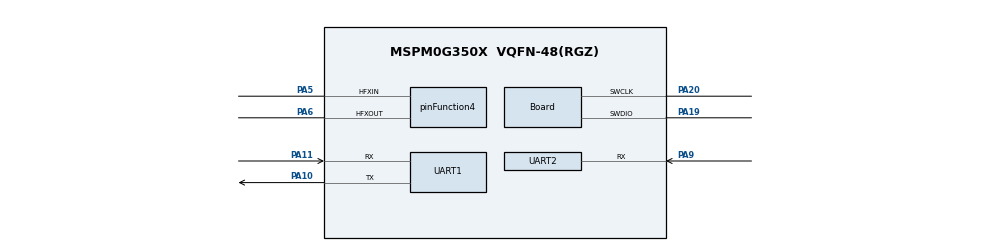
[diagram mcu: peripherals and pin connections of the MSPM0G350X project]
/**
 * @cliArgs --device "MSPM0G350X" --part "Default" --package "VQFN-48(RGZ)" --product "mspm0_sdk@2.05.01.01"
 * @versions {"tool":"1.24.0+4110"}
 */

/**
 * Import the modules used in this configuration.
 */
const SYSCTL  = scripting.addModule("/ti/driverlib/SYSCTL");
const SYSTICK = scripting.addModule("/ti/driverlib/SYSTICK");
const UART    = scripting.addModule("/ti/driverlib/UART", {}, false);
const UART1   = UART.addInstance();
const UART2   = UART.addInstance();

/**
 * Write custom configuration values to the imported modules.
 */
const divider6       = system.clockTree["PLL_CLK2X_DIV"];
divider6.divideValue = 4;

const divider9       = system.clockTree["UDIV"];
divider9.divideValue = 2;

const multiplier2         = system.clockTree["PLL_QDIV"];
multiplier2.multiplyValue = 4;

const mux4       = system.clockTree["EXHFMUX"];
mux4.inputSelect = "EXHFMUX_XTAL";

const mux8       = system.clockTree["HSCLKMUX"];
mux8.inputSelect = "HSCLKMUX_SYSPLL2X";

const mux12       = system.clockTree["SYSPLLMUX"];
mux12.inputSelect = "zSYSPLLMUX_HFCLK";

const pinFunction4                        = system.clockTree["HFXT"];
pinFunction4.inputFreq                    = 40;
pinFunction4.enable                       = true;
pinFunction4.HFXTStartup                  = 10;
pinFunction4.peripheral.$assign           = "SYSCTL";
pinFunction4.peripheral.hfxInPin.$assign  = "PA5";
pinFunction4.peripheral.hfxOutPin.$assign = "PA6";

SYSCTL.forceDefaultClkConfig = true;
SYSCTL.clockTreeEn           = true;
scripting.suppress("For best practices when the CPUCLK is running at 32MHz and above, clear the flash status bit using DL_FlashCTL_executeClearStatus\\(\\) before executing any flash operation\\. Otherwise there may be false positives\\.", SYSCTL);

const Board                       = scripting.addModule("/ti/driverlib/Board", {}, false);
Board.peripheral.$assign          = "DEBUGSS";
Board.peripheral.swclkPin.$assign = "PA20";
Board.peripheral.swdioPin.$assign = "PA19";

SYSTICK.periodEnable  = true;
SYSTICK.period        = 80;
SYSTICK.systickEnable = true;

UART1.$name                            = "UART_DEBUG";
UART1.targetBaudRate                   = 115200;
UART1.peripheral.$assign               = "UART0";
UART1.peripheral.rxPin.$assign         = "PA11";
UART1.peripheral.txPin.$assign         = "PA10";
UART1.txPinConfig.$name                = "ti_driverlib_gpio_GPIOPinGeneric0";
UART1.txPinConfig.direction            = scripting.forceWrite("OUTPUT");
UART1.txPinConfig.hideOutputInversion  = scripting.forceWrite(false);
UART1.txPinConfig.onlyInternalResistor = scripting.forceWrite(false);
UART1.txPinConfig.passedPeripheralType = scripting.forceWrite("Digital");
UART1.rxPinConfig.$name                = "ti_driverlib_gpio_GPIOPinGeneric1";
UART1.rxPinConfig.hideOutputInversion  = scripting.forceWrite(false);
UART1.rxPinConfig.onlyInternalResistor = scripting.forceWrite(false);
UART1.rxPinConfig.passedPeripheralType = scripting.forceWrite("Digital");

UART2.$name                             = "UART_COORD";
UART2.targetBaudRate                    = 115200;
UART2.direction                         = "RX";
UART2.enableFIFO                        = true;
UART2.rxTimeoutValue                    = 1;
UART2.enabledInterrupts                 = ["RX_TIMEOUT_ERROR"];
UART2.interruptPriority                 = "1";
UART2.enabledDMARXTriggers              = "DL_UART_DMA_INTERRUPT_RX";
UART2.rxPinConfig.$name                 = "ti_driverlib_gpio_GPIOPinGeneric3";
UART2.rxPinConfig.hideOutputInversion   = scripting.forceWrite(false);
UART2.rxPinConfig.onlyInternalResistor  = scripting.forceWrite(false);
UART2.rxPinConfig.passedPeripheralType  = scripting.forceWrite("Digital");
UART2.peripheral.$assign                = "UART1";
UART2.peripheral.rxPin.$assign          = "PA9";
UART2.DMA_CHANNEL_RX.$name              = "DMA_COORD";
UART2.DMA_CHANNEL_RX.addressMode        = "f2b";
UART2.DMA_CHANNEL_RX.srcLength          = "BYTE";
UART2.DMA_CHANNEL_RX.dstLength          = "BYTE";
UART2.DMA_CHANNEL_RX.peripheral.$assign = "DMA_CH0";

const ProjectConfig              = scripting.addModule("/ti/project_config/ProjectConfig", {}, false);
ProjectConfig.migrationCondition = true;
